# GD32E501 register map
File version: 1.0
GD32E501 ARM 32-bit Cortex-M33 Microcontroller based device
CPU: CM33 r0p4, little endian, MPU, FPU, 4 interrupt priority bits
Registers are 32-bit, read-write, reset 0x0 unless marked. A register's access mark holds for its fields unless they carry their own. Offsets are from the block's base; lines under a group give offsets from that group; [hi:lo] are bit positions; {n}, {i} and the like mark numbered series; 'fields as' and 'values as' point back to an identical list; <NAME> marks a mode.

## Memory map
0x40000000 TIMER1 size 0x400 — General-level0-timer
0x40000400 TIMER2 size 0x400 — General-purpose-timers
0x40001000 TIMER5 size 0x400 — Basic-timers
0x40001400 TIMER6 size 0x400 — Basic-timers
0x40002000 TIMER13 size 0x400 — General-purpose-timers
0x40002800 RTC size 0x400 — Real-time clock
0x40002C00 WWDGT size 0x400 — Window watchdog timer
0x40003000 FWDGT size 0x400 — free watchdog timer
0x40003800 SPI1 size 0x400 — Serial Peripheral Interface 1
0x40003C00 SPI2 size 0x400
0x40004400 USART1 size 0x400 — Universal synchronous asynchronous receiver transmitter
0x40005400 I2C0 size 0x400 — Inter integrated circuit
0x40005800 I2C1 size 0x400
0x40007000 PMU size 0x400 — Power management unit
0x40007400 DAC0 size 0x400 — Digital-to-analog converter
0x4000C000 I2C2 size 0x400
0x4000CC00 DAC1 size 0x400
0x4000D000 DAC2 size 0x400
0x4000D400 DAC3 size 0x400
0x4000D800 MDIO size 0x400 — Management data input/output
0x40010000 SYSCFG size 0x400 — System configuration controller
0x4001001C CMP size 0x80 — Comparator
0x40010400 EXTI size 0x400 — External interrupt/event controller
0x40012400 ADC size 0x400 — Analog to digital converter
0x40012C00 TIMER0 size 0x400 — Advanced-timers
0x40013000 SPI0 size 0x400 — Serial peripheral interface
0x40013800 USART0 size 0x400 — Universal synchronous asynchronous receiver transmitter
0x40014000 TIMER14 size 0x400 — General-purpose-timers
0x40014400 TIMER15 size 0x400 — General-purpose-timers
0x40014800 TIMER16 size 0x400
0x40020000 DMA size 0x400 — DMA controller
0x40021000 RCU size 0x400 — Reset and clock unit
0x40022000 FMC size 0x400
0x40023000 CRC size 0x400 — cyclic redundancy check calculation unit
0x40038000 CLA size 0x400 — Configurable Logic Array unit
0x48000000 GPIOA size 0x400 — General-purpose I/Os
0x48000400 GPIOB size 0x400 — General-purpose I/Os
0x48000800 GPIOC size 0x400 — General-purpose I/Os
0x48000C00 GPIOD size 0x400 — General-purpose I/Os
0x48001400 GPIOF size 0x400 — General-purpose I/Os
0xE000E100 NVIC size 0xF00 — Nested Vectored Interrupt Controller
0xE0044000 DBGMCU size 0x400 — Debug support

## Interrupts
0 WWDGT
1 LVD (EXTI)
2 RTC
3 FMC
4 RCU
5 EXTI0_1 (EXTI)
6 EXTI2_3 (EXTI)
7 EXTI4_15 (EXTI)
9 DMA_Channel0 (DMA)
10 DMA_Channel1_2 (DMA)
11 DMA_Channel3_4 (DMA)
12 ADC_CMP (ADC)
13 TIMER0_BRK_UP_TRG_COM (TIMER0)
14 TIMER0_CC (TIMER0)
15 TIMER1
16 TIMER2
17 TIMER5
18 TIMER6
19 TIMER13
20 TIMER14
21 TIMER15
22 TIMER16
23 I2C0_EV (I2C0)
24 I2C1_EV (I2C1)
25 SPI0
26 SPI1
27 USART0
28 USART1
32 I2C0_ER (I2C0)
34 I2C1_ER (I2C1)
35 I2C2_EV (I2C2)
36 I2C2_ER (I2C2)
40 MDIO
48 DMA_Channel5_6 (DMA)
73 SPI2

## ADC — Analog to digital converter
Base 0x40012400
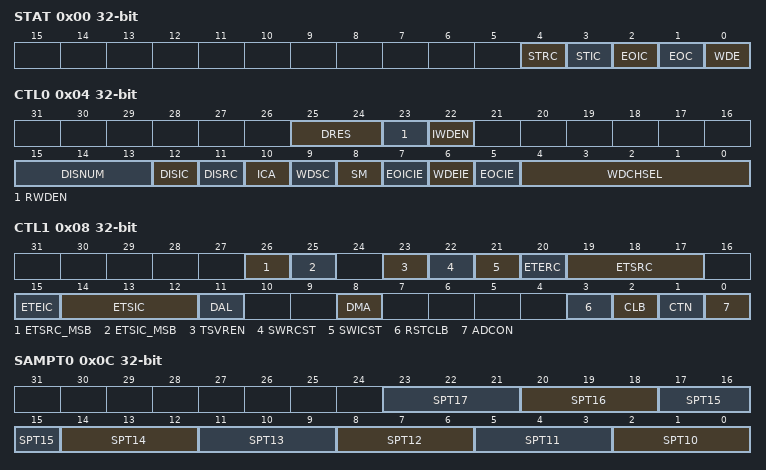
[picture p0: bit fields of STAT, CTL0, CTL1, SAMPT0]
0x00 STAT — status register
  [4] STRC — Start flag of regular channel group
  [3] STIC — Start flag of inserted channel group
  [2] EOIC — End of inserted group conversion flag
  [1] EOC — End of group conversion flag
  [0] WDE — Analog watchdog event flag
0x04 CTL0 — control register 0
  [25:24] DRES — ADC resolution
  [23] RWDEN — Regular channel analog watchdog enable
  [22] IWDEN — Inserted channel analog watchdog enable
  [15:13] DISNUM — Number of conversions in discontinuous mode
  [12] DISIC — Discontinuous mode on injected channels
  [11] DISRC — Discontinuous mode on regular channels
  [10] ICA — Inserted channel group convert automatically
  [9] WDSC — When in scan mode, analog watchdog is effective on a single channel
  [8] SM — Scan mode
  [7] EOICIE — Interrupt enable for EOIC
  [6] WDEIE — Interrupt enable for WDE
  [5] EOCIE — Interrupt enable for EOC
  [4:0] WDCHSEL — Analog watchdog channel select
0x08 CTL1 — control register 1
  [26] ETSRC_MSB — External trigger select for regular channel
  [25] ETSIC_MSB — External trigger select for inserted channel
  [23] TSVREN — Channel 16 and 17 enable of ADC
  [22] SWRCST — Start on regular channel
  [21] SWICST — Start on inserted channel
  [20] ETERC — External trigger enable for regular channel
  [19:17] ETSRC — External trigger select for regular channel
  [15] ETEIC — External trigger enable for inserted channels
  [14:12] ETSIC — External trigger select for inserted channel
  [11] DAL — Data alignment
  [8] DMA — DMA request enable
  [3] RSTCLB — Reset calibration
  [2] CLB — ADC calibration
  [1] CTN — Continuous mode
  [0] ADCON
0x0C SAMPT0 — Sampling time register 0
  [3n-28:3n-30] SPT{n} (n=10..17) — Channel {n} sample time selection
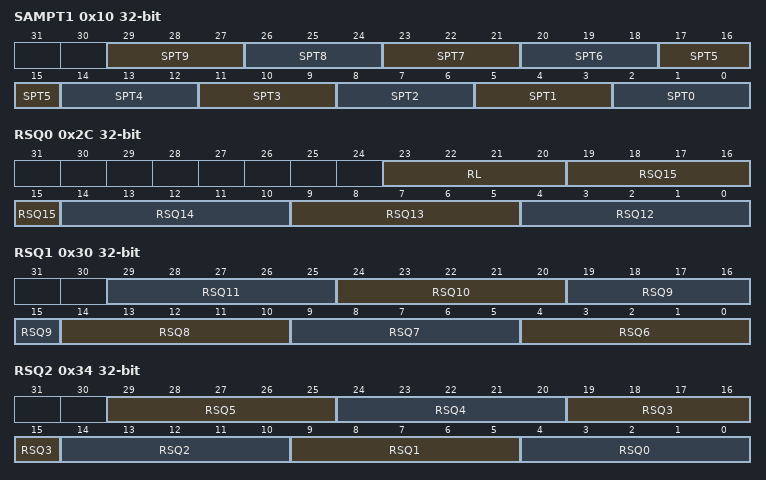
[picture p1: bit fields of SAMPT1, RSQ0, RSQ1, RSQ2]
0x10 SAMPT1 — Sampling time register 1
  [3n+2:3n] SPT{n} (n=1..9) — Channel {n} sample time selection
  [2:0] SPT0 — Channel 9 sample time selection
{0x14+4i} IOFF{i} (i=0..3) — Inserted channel data offset register {i}
  [11:0] IOFF — Data offset for injected channel x
0x24 WDHT reset 0xFFF — watchdog higher threshold register
  [11:0] WDHT — Analog watchdog high threshold
0x28 WDLT — watchdog low threshold register
  [11:0] WDLT — Analog watchdog lower threshold
0x2C RSQ0 — regular sequence register 0
  [23:20] RL — Regular channel sequence length
  [5n-56:5n-60] RSQ{n} (n=12..15) — {n}th conversion in regular sequence
0x30 RSQ1 — regular sequence register 1
  [5n-26:5n-30] RSQ{n} (n=6..11) — {n}th conversion in regular sequence
0x34 RSQ2 — regular sequence register 2
  [29:25] RSQ5 — 5th conversion in regular sequence
  [24:20] RSQ4 — 4th conversion in regular sequence
  [19:15] RSQ3 — 3rd conversion in regular sequence
  [14:10] RSQ2 — 2nd conversion in regular sequence
  [9:5] RSQ1 — 1st conversion in regular sequence
  [4:0] RSQ0 — conversion in regular sequence
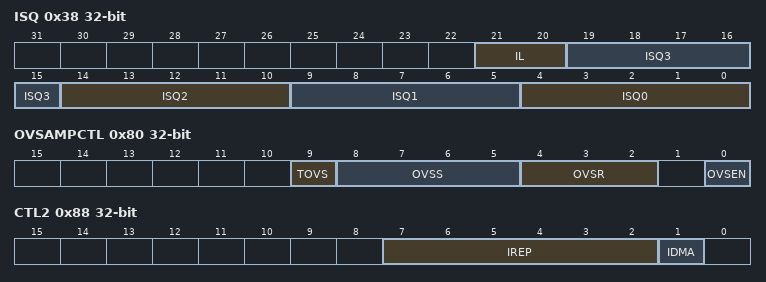
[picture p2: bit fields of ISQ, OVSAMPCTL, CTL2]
0x38 ISQ — inserted sequence register
  [21:20] IL — Inserted sequence length
  [19:15] ISQ3 — 3rd conversion in inserted sequence
  [14:10] ISQ2 — 2nd conversion in inserted sequence
  [9:5] ISQ1 — 1st conversion in inserted sequence
  [4:0] ISQ0 — conversion in inserted sequence
{0x3C+4i} IDATA{i} ro (i=0..3) — inserted data register {i}
  [15:0] IDATAn — inserted data
0x4C RDATA ro — regular data register
  [15:0] RDATA — Regular data
0x80 OVSAMPCTL — ADC oversample control register
  [9] TOVS — Triggered Oversampling
  [8:5] OVSS — Oversampling shift
  [4:2] OVSR — Oversampling ratio
  [0] OVSEN — Oversampler Enable
0x88 CTL2 — control register 2
  [7:2] IREP — Inject group repeat times
  [1] IDMA — DMA request enable for Inject channel
